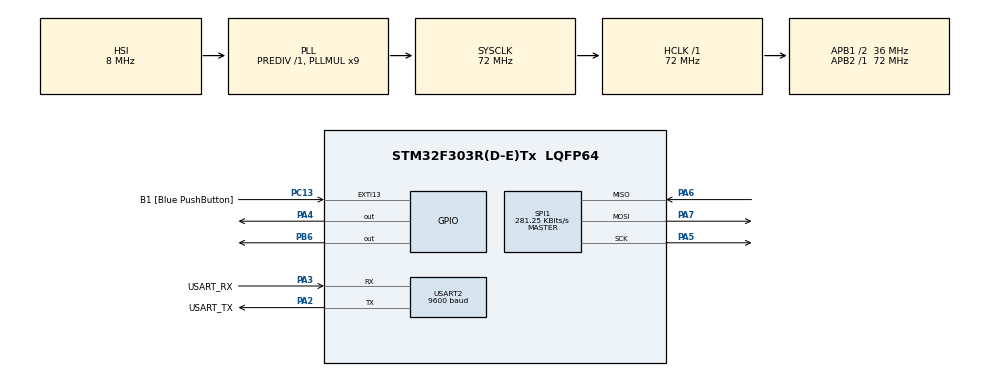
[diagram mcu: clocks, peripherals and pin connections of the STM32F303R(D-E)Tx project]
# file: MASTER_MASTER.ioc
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Mcu.Family=STM32F3
Mcu.Name=STM32F303R(D-E)Tx
Mcu.Package=LQFP64
NVIC.PriorityGroup=NVIC_PRIORITYGROUP_0
NVIC.SPI1_IRQn=true\:0\:0\:false\:false\:true\:true\:true\:true
NVIC.USART2_IRQn=true\:0\:0\:false\:false\:true\:true\:true\:true
PA13.GPIO_Label=TMS
PA13.Signal=SYS_JTMS-SWDIO
PA14.GPIO_Label=TCK
PA14.Signal=SYS_JTCK-SWCLK
PA2.GPIO_Label=USART_TX
PA2.GPIO_Mode=GPIO_MODE_AF_PP
PA2.GPIO_PuPd=GPIO_NOPULL
PA2.GPIO_Speed=GPIO_SPEED_FREQ_LOW
PA2.Mode=Asynchronous
PA2.Signal=USART2_TX
PA3.GPIO_Label=USART_RX
PA3.GPIO_Mode=GPIO_MODE_AF_PP
PA3.GPIO_PuPd=GPIO_NOPULL
PA3.GPIO_Speed=GPIO_SPEED_FREQ_LOW
PA3.Mode=Asynchronous
PA3.Signal=USART2_RX
PA4.Signal=GPIO_Output
PA5.Mode=Full_Duplex_Master
PA5.Signal=SPI1_SCK
PA6.Mode=Full_Duplex_Master
PA6.Signal=SPI1_MISO
PA7.Mode=Full_Duplex_Master
PA7.Signal=SPI1_MOSI
PB3.GPIO_Label=SWO
PB3.Signal=SYS_JTDO-TRACESWO
PB6.Signal=GPIO_Output
PC13.GPIO_Label=B1 [Blue PushButton]
PC13.GPIO_ModeDefaultEXTI=GPIO_MODE_IT_FALLING
PC13.Signal=GPXTI13
PC14-OSC32_IN.Signal=RCC_OSC32_IN
PC15-OSC32_OUT.Signal=RCC_OSC32_OUT
PF0-OSC_IN.Signal=RCC_OSC_IN
PF1-OSC_OUT.Signal=RCC_OSC_OUT
ProjectManager.HeapSize=0x200
ProjectManager.StackSize=0x400
ProjectManager.TargetToolchain=STM32CubeIDE
RCC.AHBFreq_Value=72000000
RCC.APB1CLKDivider=RCC_HCLK_DIV2
RCC.APB1Freq_Value=36000000
RCC.APB1TimFreq_Value=72000000
RCC.APB2Freq_Value=72000000
RCC.APB2TimFreq_Value=72000000
RCC.CortexFreq_Value=72000000
RCC.HCLKFreq_Value=72000000
RCC.HSE_VALUE=8000000
RCC.HSI_VALUE=8000000
RCC.LSE_VALUE=32768
RCC.PLLM=8
RCC.PLLMUL=RCC_PLL_MUL9
RCC.PLLN=336
RCC.PLLP=RCC_PLLP_DIV4
RCC.PLLQ=7
RCC.RCC_PLLsource_Clock_Source_FROM_HSE=RCC_HSE_PREDIV_DIV2
RCC.SYSCLKFreq_VALUE=72000000
RCC.SYSCLKSourceVirtual=RCC_SYSCLKSOURCE_PLLCLK
RCC.USBFreq_Value=72000000
SPI1.BaudRatePrescaler=SPI_BAUDRATEPRESCALER_256
SPI1.CalculateBaudRate=281.25 KBits/s
SPI1.DataSize=SPI_DATASIZE_8BIT
SPI1.Direction=SPI_DIRECTION_2LINES
SPI1.Mode=SPI_MODE_MASTER
SPI1.VirtualType=VM_MASTER
USART2.BaudRate=9600
USART2.VirtualMode-Asynchronous=VM_ASYNC
board=NUCLEO-F303RE

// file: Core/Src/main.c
/* USER CODE BEGIN Header */
/**
  ******************************************************************************
  * @file           : main.c
  * @brief          : Main program body
  ******************************************************************************
  * @attention
  *
  * Copyright (c) 2024 STMicroelectronics.
  * All rights reserved.
  *
  * This software is licensed under terms that can be found in the LICENSE file
  * in the root directory of this software component.
  * If no LICENSE file comes with this software, it is provided AS-IS.
  *
  ******************************************************************************
  */
/* USER CODE END Header */
#include "main.h"

SPI_HandleTypeDef hspi1;

UART_HandleTypeDef huart2;
/* USER CODE BEGIN PV */

#define MAX_MSG_LENGTH 50  // Ajusta este valor si es necesario

char spi_tx_buf[MAX_MSG_LENGTH + 1];  // Buffer para el mensaje recibido
char uart_buf[100];  // Buffer para mensajes de UART
int uart_buf_len;
uint8_t msg_length;
uint8_t msg_length_digits[2];  // Para almacenar los dos dígitos del primer byte
int slave_selector;  // Variable para seleccionar el slave

/* USER CODE END PV */

void SystemClock_Config(void);
static void MX_GPIO_Init(void);
static void MX_SPI1_Init(void);
static void MX_USART2_UART_Init(void);

int main(void)
{

  /* MCU Configuration--------------------------------------------------------*/

  /* Reset of all peripherals, Initializes the Flash interface and the Systick. */
  HAL_Init();

  /* Configure the system clock */
  SystemClock_Config();

  /* Initialize all configured peripherals */
  MX_GPIO_Init();
  MX_SPI1_Init();
  MX_USART2_UART_Init();
  /* USER CODE BEGIN 2 */

  /* Infinite loop */
  uart_buf_len = sprintf(uart_buf, "LISTO PARA ENVIAR");
  /* USER CODE BEGIN 2 */
  while (1)
  {
      // Recibe el selector del slave
      if (HAL_UART_Receive(&huart2, &slave_selector, 1, HAL_MAX_DELAY) == HAL_OK)
      {
          // Convierte el carácter recibido al número real del selector
          slave_selector -= '0';  // '0' tiene el valor 48, así que restamos 48 para obtener el número real

          // Ajusta el GPIO para seleccionar el slave adecuado
          if (slave_selector == 1)  // Selecciona GPIOA4
          {
              HAL_GPIO_WritePin(GPIOA, GPIO_PIN_4, GPIO_PIN_RESET);  // Activa GPIOA4
              HAL_GPIO_WritePin(GPIOB, GPIO_PIN_6, GPIO_PIN_SET);    // Desactiva GPIOB6
          }
          else if (slave_selector == 2)  // Selecciona GPIOB6
          {
              HAL_GPIO_WritePin(GPIOA, GPIO_PIN_4, GPIO_PIN_SET);    // Desactiva GPIOA4
              HAL_GPIO_WritePin(GPIOB, GPIO_PIN_6, GPIO_PIN_RESET);  // Activa GPIOB6
          }
          else
          {
              uart_buf_len = sprintf(uart_buf, "Selector de slave no válido: %d\r\n", slave_selector);
              HAL_UART_Transmit(&huart2, (uint8_t *)uart_buf, uart_buf_len, HAL_MAX_DELAY);
              continue;  // Continúa con el siguiente ciclo del bucle
          }

          // Recibe el primer byte que contiene los dos dígitos del tamaño del mensaje
          if (HAL_UART_Receive(&huart2, (uint8_t *)msg_length_digits, 2, HAL_MAX_DELAY) == HAL_OK)
          {
              // Procesa el primer dígito para la longitud del mensaje
              msg_length = (msg_length_digits[0] - '0') * 10 + (msg_length_digits[1] - '0');

              if (msg_length > MAX_MSG_LENGTH)
                  msg_length = MAX_MSG_LENGTH;  // Limita el tamaño del mensaje

              // Recibe el mensaje completo
              if (HAL_UART_Receive(&huart2, (uint8_t *)spi_tx_buf, msg_length, HAL_MAX_DELAY) == HAL_OK)
              {
                  // Envía el mensaje recibido al slave seleccionado
                  HAL_SPI_Transmit(&hspi1, (uint8_t *)spi_tx_buf, msg_length, HAL_MAX_DELAY);

                  // Mensaje de confirmación
                  uart_buf_len = sprintf(uart_buf, "Mensaje enviado al slave %d: %s\r\n", slave_selector, spi_tx_buf);
                  HAL_UART_Transmit(&huart2, (uint8_t *)uart_buf, uart_buf_len, HAL_MAX_DELAY);

                  // Después de la transmisión, libera el pin NSS
                  if (slave_selector == 1)
                  {
                      HAL_GPIO_WritePin(GPIOA, GPIO_PIN_4, GPIO_PIN_SET);  // Desactiva GPIOA4
                  }
                  else if (slave_selector == 2)
                  {
                      HAL_GPIO_WritePin(GPIOB, GPIO_PIN_6, GPIO_PIN_SET);  // Desactiva GPIOB6
                  }

              }
          }
      }
    }
}

void SystemClock_Config(void)
{
  RCC_OscInitTypeDef RCC_OscInitStruct = {0};
  RCC_ClkInitTypeDef RCC_ClkInitStruct = {0};
  RCC_PeriphCLKInitTypeDef PeriphClkInit = {0};

  /** Initializes the RCC Oscillators according to the specified parameters
  * in the RCC_OscInitTypeDef structure.
  */
  RCC_OscInitStruct.OscillatorType = RCC_OSCILLATORTYPE_HSI;
  RCC_OscInitStruct.HSIState = RCC_HSI_ON;
  RCC_OscInitStruct.HSICalibrationValue = RCC_HSICALIBRATION_DEFAULT;
  RCC_OscInitStruct.PLL.PLLState = RCC_PLL_ON;
  RCC_OscInitStruct.PLL.PLLSource = RCC_PLLSOURCE_HSI;
  RCC_OscInitStruct.PLL.PLLMUL = RCC_PLL_MUL9;
  RCC_OscInitStruct.PLL.PREDIV = RCC_PREDIV_DIV1;
  if (HAL_RCC_OscConfig(&RCC_OscInitStruct) != HAL_OK)
  {
    Error_Handler();
  }

  /** Initializes the CPU, AHB and APB buses clocks
  */
  RCC_ClkInitStruct.ClockType = RCC_CLOCKTYPE_HCLK|RCC_CLOCKTYPE_SYSCLK
                              |RCC_CLOCKTYPE_PCLK1|RCC_CLOCKTYPE_PCLK2;
  RCC_ClkInitStruct.SYSCLKSource = RCC_SYSCLKSOURCE_PLLCLK;
  RCC_ClkInitStruct.AHBCLKDivider = RCC_SYSCLK_DIV1;
  RCC_ClkInitStruct.APB1CLKDivider = RCC_HCLK_DIV2;
  RCC_ClkInitStruct.APB2CLKDivider = RCC_HCLK_DIV1;

  if (HAL_RCC_ClockConfig(&RCC_ClkInitStruct, FLASH_LATENCY_2) != HAL_OK)
  {
    Error_Handler();
  }
  PeriphClkInit.PeriphClockSelection = RCC_PERIPHCLK_USART2;
  PeriphClkInit.Usart2ClockSelection = RCC_USART2CLKSOURCE_PCLK1;
  if (HAL_RCCEx_PeriphCLKConfig(&PeriphClkInit) != HAL_OK)
  {
    Error_Handler();
  }
}

static void MX_SPI1_Init(void)
{

  /* SPI1 parameter configuration*/
  hspi1.Instance = SPI1;
  hspi1.Init.Mode = SPI_MODE_MASTER;
  hspi1.Init.Direction = SPI_DIRECTION_2LINES;
  hspi1.Init.DataSize = SPI_DATASIZE_8BIT;
  hspi1.Init.CLKPolarity = SPI_POLARITY_LOW;
  hspi1.Init.CLKPhase = SPI_PHASE_1EDGE;
  hspi1.Init.NSS = SPI_NSS_SOFT;
  hspi1.Init.BaudRatePrescaler = SPI_BAUDRATEPRESCALER_256;
  hspi1.Init.FirstBit = SPI_FIRSTBIT_MSB;
  hspi1.Init.TIMode = SPI_TIMODE_DISABLE;
  hspi1.Init.CRCCalculation = SPI_CRCCALCULATION_DISABLE;
  hspi1.Init.CRCPolynomial = 7;
  hspi1.Init.CRCLength = SPI_CRC_LENGTH_DATASIZE;
  hspi1.Init.NSSPMode = SPI_NSS_PULSE_ENABLE;
  if (HAL_SPI_Init(&hspi1) != HAL_OK)
  {
    Error_Handler();
  }

}

static void MX_USART2_UART_Init(void)
{

  huart2.Instance = USART2;
  huart2.Init.BaudRate = 9600;
  huart2.Init.WordLength = UART_WORDLENGTH_8B;
  huart2.Init.StopBits = UART_STOPBITS_1;
  huart2.Init.Parity = UART_PARITY_NONE;
  huart2.Init.Mode = UART_MODE_TX_RX;
  huart2.Init.HwFlowCtl = UART_HWCONTROL_NONE;
  huart2.Init.OverSampling = UART_OVERSAMPLING_16;
  huart2.Init.OneBitSampling = UART_ONE_BIT_SAMPLE_DISABLE;
  huart2.AdvancedInit.AdvFeatureInit = UART_ADVFEATURE_NO_INIT;
  if (HAL_UART_Init(&huart2) != HAL_OK)
  {
    Error_Handler();
  }

}

static void MX_GPIO_Init(void)
{
  GPIO_InitTypeDef GPIO_InitStruct = {0};

  /* GPIO Ports Clock Enable */
  __HAL_RCC_GPIOC_CLK_ENABLE();
  __HAL_RCC_GPIOF_CLK_ENABLE();
  __HAL_RCC_GPIOA_CLK_ENABLE();
  __HAL_RCC_GPIOB_CLK_ENABLE();

  /*Configure GPIO pin Output Level */
  HAL_GPIO_WritePin(GPIOA, GPIO_PIN_4, GPIO_PIN_SET);

  /*Configure GPIO pin Output Level */
  HAL_GPIO_WritePin(GPIOB, GPIO_PIN_6, GPIO_PIN_SET);

  /*Configure GPIO pin : B1_Pin */
  GPIO_InitStruct.Pin = B1_Pin;
  GPIO_InitStruct.Mode = GPIO_MODE_IT_FALLING;
  GPIO_InitStruct.Pull = GPIO_NOPULL;
  HAL_GPIO_Init(B1_GPIO_Port, &GPIO_InitStruct);

  /*Configure GPIO pin : PA4 */
  GPIO_InitStruct.Pin = GPIO_PIN_4;
  GPIO_InitStruct.Mode = GPIO_MODE_OUTPUT_PP;
  GPIO_InitStruct.Pull = GPIO_NOPULL;
  GPIO_InitStruct.Speed = GPIO_SPEED_FREQ_LOW;
  HAL_GPIO_Init(GPIOA, &GPIO_InitStruct);

  /*Configure GPIO pin : PB6 */
  GPIO_InitStruct.Pin = GPIO_PIN_6;
  GPIO_InitStruct.Mode = GPIO_MODE_OUTPUT_PP;
  GPIO_InitStruct.Pull = GPIO_NOPULL;
  GPIO_InitStruct.Speed = GPIO_SPEED_FREQ_LOW;
  HAL_GPIO_Init(GPIOB, &GPIO_InitStruct);

}

void Error_Handler(void)
{
  __disable_irq();
  while (1)
  {
  }
}
